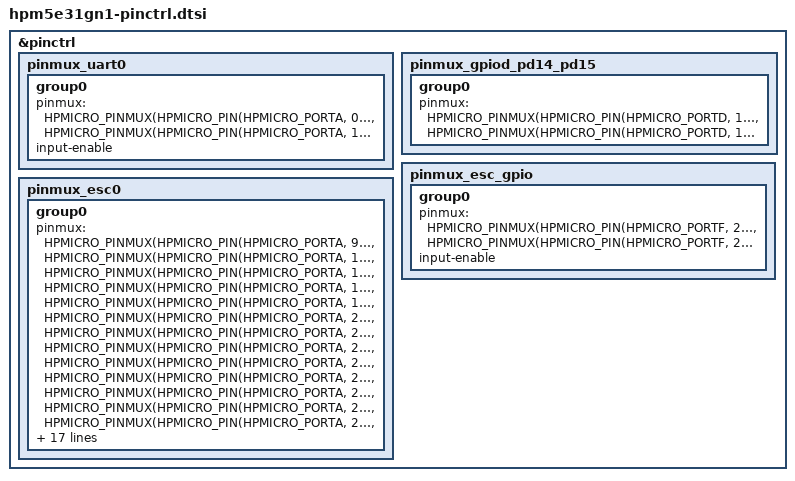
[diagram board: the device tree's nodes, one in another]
#include <dt-bindings/pinctrl/hpmicro-pinctrl-common.h>

&pinctrl {
	pinmux_uart0: pinmux_uart0 {
		group0 {
			pinmux = <HPMICRO_PINMUX(HPMICRO_PIN(HPMICRO_PORTA, 0), IOC_TYPE_IOC, 0, 2)>,
					 <HPMICRO_PINMUX(HPMICRO_PIN(HPMICRO_PORTA, 1), IOC_TYPE_IOC, 0, 2)>;
			input-enable;
		};
	};

	pinmux_gpiod_pd14_pd15: pinmux_gpiod_pd14_pd15 {
		group0 {
			pinmux = <HPMICRO_PINMUX(HPMICRO_PIN(HPMICRO_PORTD, 14), IOC_TYPE_IOC, 0, 0)>,
					 <HPMICRO_PINMUX(HPMICRO_PIN(HPMICRO_PORTD, 15), IOC_TYPE_IOC, 0, 0)>;
		};
	};

	pinmux_esc_gpio: pinmux_esc_gpio {
		group0 {
			pinmux = <HPMICRO_PINMUX(HPMICRO_PIN(HPMICRO_PORTF, 26), IOC_TYPE_IOC, 0, 0)>,
					 <HPMICRO_PINMUX(HPMICRO_PIN(HPMICRO_PORTF, 28), IOC_TYPE_IOC, 0, 0)>;
			input-enable;
		};
	};

	pinmux_esc0: pinmux_esc0 {
		group0 {
			pinmux = <HPMICRO_PINMUX(HPMICRO_PIN(HPMICRO_PORTA, 9), IOC_TYPE_IOC, 0, 11)>,
					 <HPMICRO_PINMUX(HPMICRO_PIN(HPMICRO_PORTA, 16), IOC_TYPE_IOC, 0, 11)>,
					 <HPMICRO_PINMUX(HPMICRO_PIN(HPMICRO_PORTA, 17), IOC_TYPE_IOC, 0, 11)>,
					 <HPMICRO_PINMUX(HPMICRO_PIN(HPMICRO_PORTA, 18), IOC_TYPE_IOC, 0, 11)>,
					 <HPMICRO_PINMUX(HPMICRO_PIN(HPMICRO_PORTA, 19), IOC_TYPE_IOC, 0, 11)>,
					 <HPMICRO_PINMUX(HPMICRO_PIN(HPMICRO_PORTA, 20), IOC_TYPE_IOC, 0, 11)>,
					 <HPMICRO_PINMUX(HPMICRO_PIN(HPMICRO_PORTA, 21), IOC_TYPE_IOC, 0, 11)>,
					 <HPMICRO_PINMUX(HPMICRO_PIN(HPMICRO_PORTA, 23), IOC_TYPE_IOC, 0, 11)>,
					 <HPMICRO_PINMUX(HPMICRO_PIN(HPMICRO_PORTA, 24), IOC_TYPE_IOC, 0, 11)>,
					 <HPMICRO_PINMUX(HPMICRO_PIN(HPMICRO_PORTA, 25), IOC_TYPE_IOC, 0, 11)>,
					 <HPMICRO_PINMUX(HPMICRO_PIN(HPMICRO_PORTA, 26), IOC_TYPE_IOC, 0, 11)>,
					 <HPMICRO_PINMUX(HPMICRO_PIN(HPMICRO_PORTA, 27), IOC_TYPE_IOC, 0, 11)>,
					 <HPMICRO_PINMUX(HPMICRO_PIN(HPMICRO_PORTA, 28), IOC_TYPE_IOC, 0, 11)>,
					 <HPMICRO_PINMUX(HPMICRO_PIN(HPMICRO_PORTA, 29), IOC_TYPE_IOC, 0, 11)>,
					 <HPMICRO_PINMUX(HPMICRO_PIN(HPMICRO_PORTA, 30), IOC_TYPE_IOC, 0, 11)>,
					 <HPMICRO_PINMUX(HPMICRO_PIN(HPMICRO_PORTA, 31), IOC_TYPE_IOC, 0, 11)>,
					 <HPMICRO_PINMUX(HPMICRO_PIN(HPMICRO_PORTF, 2), IOC_TYPE_IOC, 0, 11)>,
					 <HPMICRO_PINMUX(HPMICRO_PIN(HPMICRO_PORTF, 3), IOC_TYPE_IOC, 0, 11)>,
					 <HPMICRO_PINMUX(HPMICRO_PIN(HPMICRO_PORTF, 4), IOC_TYPE_IOC, 0, 11)>,
					 <HPMICRO_PINMUX(HPMICRO_PIN(HPMICRO_PORTF, 5), IOC_TYPE_IOC, 0, 11)>,
					 <HPMICRO_PINMUX(HPMICRO_PIN(HPMICRO_PORTF, 6), IOC_TYPE_IOC, 0, 11)>,
					 <HPMICRO_PINMUX(HPMICRO_PIN(HPMICRO_PORTF, 7), IOC_TYPE_IOC, 0, 11)>,
					 <HPMICRO_PINMUX(HPMICRO_PIN(HPMICRO_PORTF, 8), IOC_TYPE_IOC, 0, 11)>,
					 <HPMICRO_PINMUX(HPMICRO_PIN(HPMICRO_PORTF, 9), IOC_TYPE_IOC, 0, 11)>,
					 <HPMICRO_PINMUX(HPMICRO_PIN(HPMICRO_PORTF, 10), IOC_TYPE_IOC, 0, 11)>,
					 <HPMICRO_PINMUX(HPMICRO_PIN(HPMICRO_PORTF, 11), IOC_TYPE_IOC, 0, 11)>,
					 <HPMICRO_PINMUX(HPMICRO_PIN(HPMICRO_PORTF, 12), IOC_TYPE_IOC, 0, 11)>,
					 <HPMICRO_PINMUX(HPMICRO_PIN(HPMICRO_PORTF, 13), IOC_TYPE_IOC, 0, 11)>,
					 <HPMICRO_PINMUX(HPMICRO_PIN(HPMICRO_PORTF, 14), IOC_TYPE_IOC, 0, 11)>;
			input-enable;
		};
	};
};
